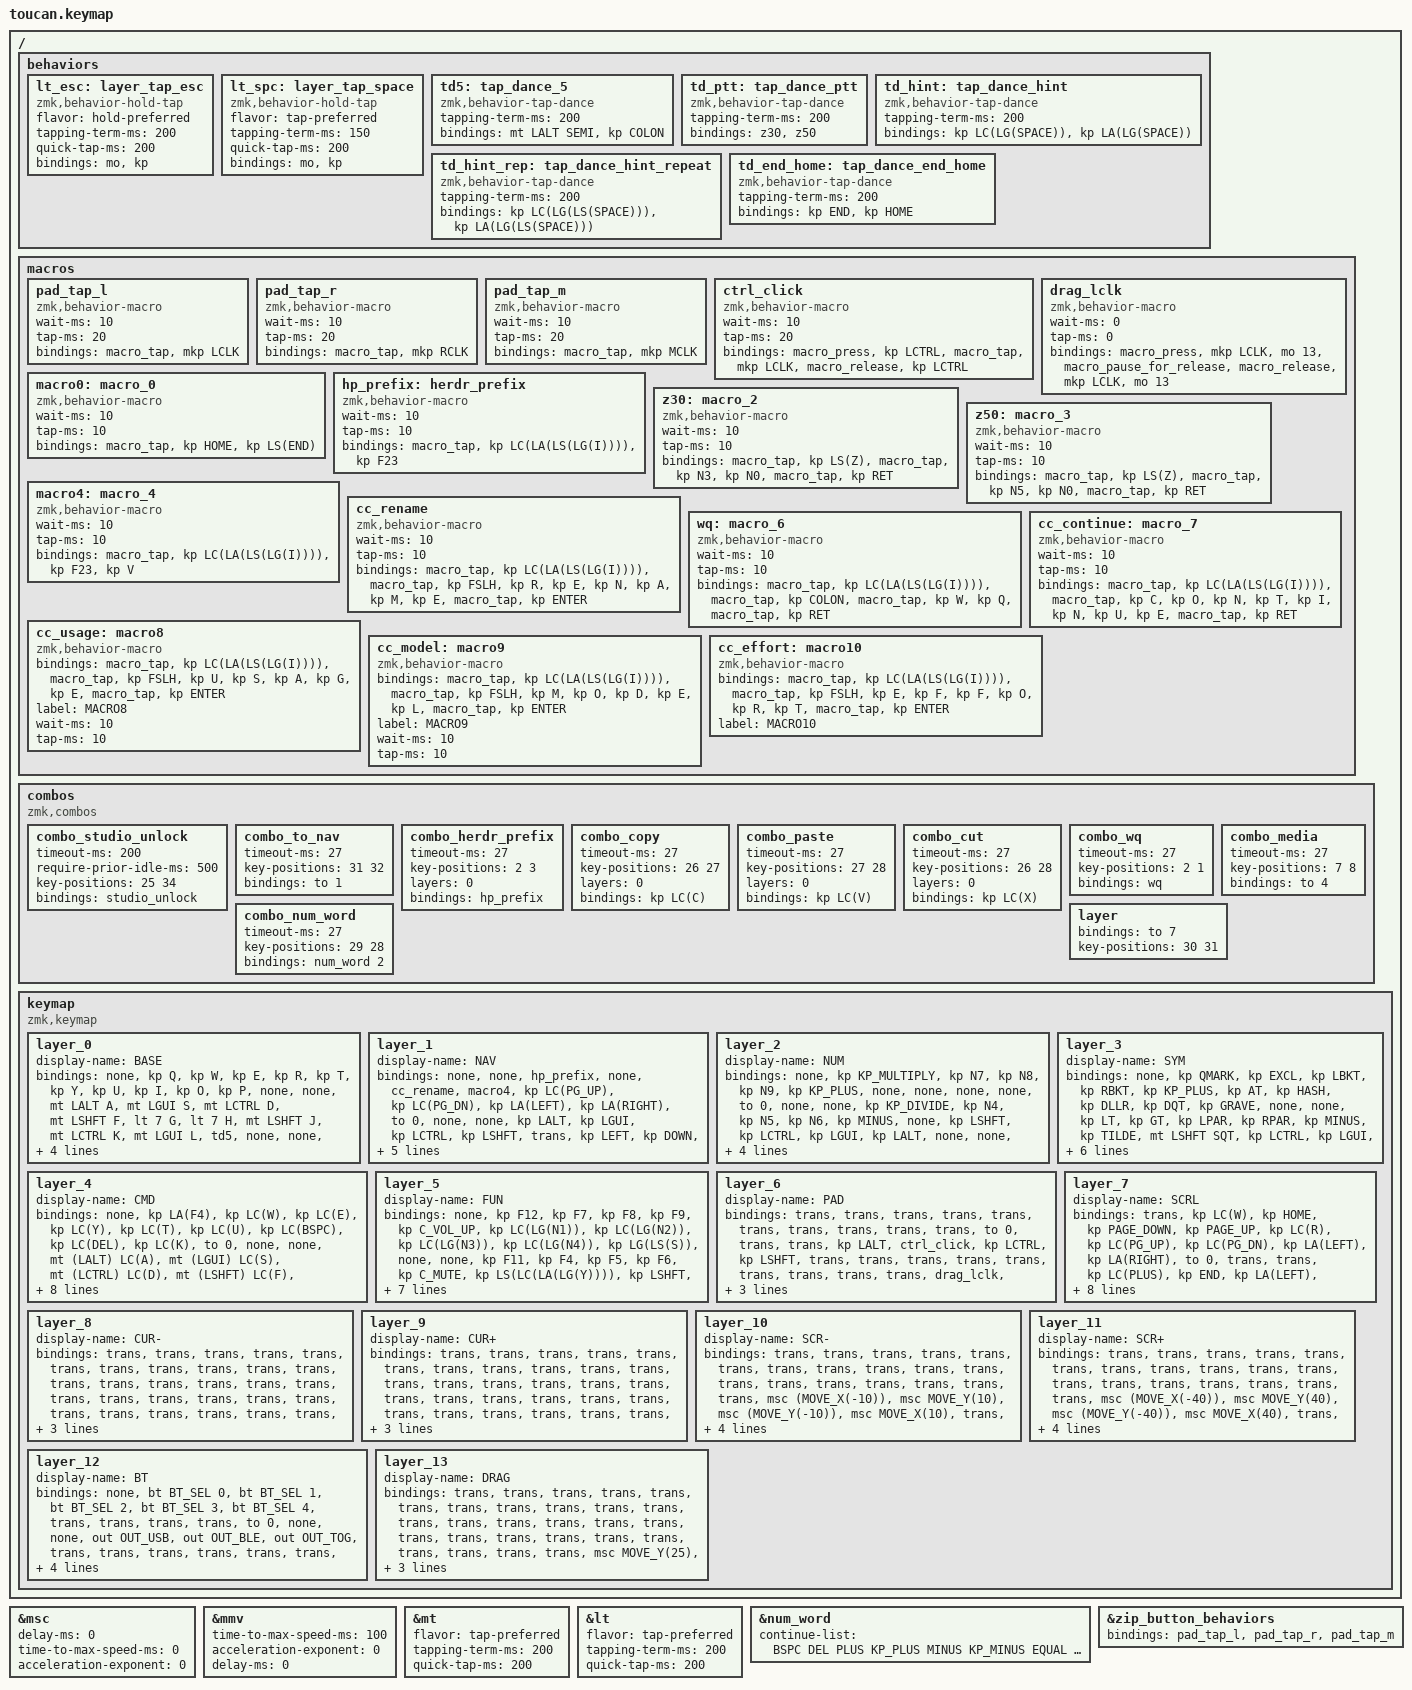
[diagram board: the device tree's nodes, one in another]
/*
 * beekeeb Toucan (dongle mode) keymap
 *
 * ⚠️ ── 2026-09-22：本檔與 Vial/QMK 正式分家，不再同步 ────────────────────
 *
 * 本檔原本是 keyboard-manager 從 beekeeb 36key.vil 產生的，檔頭寫著「do not
 * hand-edit if you intend to regenerate — change the layout in Vial, re-export,
 * and diff」。**該約定自 2026-09-22 起作廢。**
 *
 *   • 這份 ZMK keymap 是 Toucan 的**唯一真相來源**，直接手改即可。
 *   • **不要**再從 .vil 重新產生，那會洗掉底下所有 ZMK 專屬的東西——
 *     per-key hold-tap（lt_esc / lt_spc）、combos、input processor、
 *     tap-dance、num_word 的 continue-list，QMK 那邊沒有對應概念。
 *   • Piantor (Vial/QMK) 那把從此各走各的，兩邊**刻意允許發散**。
 *     `piantor/README.md` 那份「.vil 落後清單」不必再維護。
 *
 * ── 「同步」從此只有一個意思：同一把鍵盤的兩個作業系統 ────────────────────
 *
 *     同步軸                                             要不要同步
 *     ────────────────────────────────────────────────────────────
 *     ZMK：prospector-scanner(mac) ↔ …-windows(win)          ✅ 要
 *     QMK：piantor-macos-*.vil    ↔ piantor-windows-*.vil    ✅ 要
 *     ZMK ↔ QMK（Toucan ↔ Piantor）                          ❌ 不要
 *
 * 也就是 **跨 OS 要同步、跨韌體不同步**。以後講「同步」都是指前兩列。
 *
 * ⚠️ 所以根目錄 CLAUDE.md 那條「功能性改動（新增／移動／刪除某顆鍵、滾動
 *    方向）要兩個分支都做」**仍然完全有效** —— 它講的是第一列（ZMK 的兩個
 *    平台分支），跟本段作廢的 Vial 那條線無關。鍵碼各自用該平台的原生寫法
 *    （Ctrl ↔ ⌘）。不要把這兩條線搞混。
 *
 * CONVERSION-REPORT.md 仍可讀，但它只是當年一次性轉檔的歷史紀錄，
 * 不再是需要對齊的規格。
 */
/*
 * ── 本分支（prospector-scanner-windows）＝ Windows 版 ───────────────────
 *
 * 2026-09-07 從 prospector-scanner 分出來。原則：**操作語意一致，鍵碼各自
 * 原生**——不是傻傻地把 Cmd 換成 Ctrl，每一顆都對到 Windows 真正的做法。
 * 對照的權威來源是 piantor/README.md（Piantor Pro 就是這套 layout 的
 * Windows 版，2026-09-04 已實機驗證），本檔完全沿用那份定案：
 *
 *   分頁切換        ⇧⌘[ / ⇧⌘]      → Ctrl+PgUp / Ctrl+PgDn
 *   瀏覽歷史        ⌘[ / ⌘]        → Alt+← / Alt+→
 *   關程式          ⌘Q             → Alt+F4
 *   重做            ⇧⌘Z            → Ctrl+Y
 *   關/開分頁       ⌘W / ⌘T        → Ctrl+W / Ctrl+T
 *   剪貼/復原等     ⌘Z X C V B...  → Ctrl+同字母
 *   行首/行尾       ⌘← / ⌘→        → Home / End
 *   跳字            ⌥← / ⌥→        → Ctrl+← / Ctrl+→（選取加 Shift 同理）
 *   四顆刪除鍵(YUIO) ⌘⌫ ⌥⌫ ⌥⌦ ⌃K   → Ctrl+U / Ctrl+⌫ / Ctrl+Del / Ctrl+K
 *   截圖            ⇧⌘5            → Win+Shift+S
 *   切輸入法        F18            → F18（兩平台同鍵碼；Windows 由 AHK 的 $F18:: 接走）
 *   縮放            ⌘+ / ⌘0        → Ctrl+= / Ctrl+0
 *   重新整理        ⌘R             → Ctrl+R
 *   同程式切視窗    ⌘`             → Alt+Esc（Windows 沒有原生同程式循環，
 *                                     Alt+Esc 是最接近的免選單循環切換）
 *   app 焦點熱鍵    Hyper+L/E/F/T  → Ctrl+Win+1~4（工作列釘選 1~4 號）
 *   NUM 層數字      KP_N0~9/KP_DOT → 數字列 N0~9 / DOT（NumLock 關閉時
 *                                     KP_7 在 Windows 會變 Home，全部避開）
 *
 * 不變的：Hyper 巨集（⌃⌥⇧⌘+字母，HID 兩邊相同，主機端 AHK 接手）、
 * Alt+P / Alt+Space / Ctrl+Space(tmux) / Ctrl+K / F19、所有打字巨集、
 * home row 裸修飾鍵（fb3fc56 起兩把鍵盤就是「位置一致」：S=GUI、D=Ctrl）。
 *
 * ⚠️ 切輸入法 2026-10-02 起不再送 `LG(SPACE)`：鍵盤送真的 Win 時，只要放開
 *    Win 的瞬間落進 AHK 注入 Ctrl+Space 的那 1–2ms，Win 就會漏給 shell、
 *    **開始功能表跳出來**（KeyHistory 實拍：實體 LWin up 夾在注入的 Ctrl
 *    down/up 中間）。改送 F18 之後 Win 根本不出現，競態沒有地方發生。
 *    筆電內建鍵盤的 Win+Space 仍由 AHK 的 `$#Space::` 接。
 *
 * ⚠️ 下方歷史註解裡提到的 mac 鍵碼（LG(W) 之類）維持原文不改，讀的時候
 *    對照本表換算即可。
 */
/*
 * ── 層名：全部 ≤ 4 字元，這是硬約束 ─────────────────────────────────────
 *
 * 2026-09-03 改名。三個獨立的理由指向同一個上限：
 *
 *   1. Prospector 廣播欄位 `layer_name[4]` 就是 4 bytes（見
 *      status_advertisement.h）。超過直接截斷，而截斷會「撞名」——舊的
 *      CUR SLOWEST / CUR SLOW / CUR FAST 三層全部塌成 "CUR "，
 *      三個 SCRL 檔全部塌成 "SCRL"，NAV SCRL 撞 NAV。
 *   2. dongle 的儀表板版面把層名排成固定 50px 單行、不 wrap 不縮字。
 *      只要每個名字都 ≤4 字，溢出就不是「大概不會」而是不可能。
 *   3. 鍵盤自己的 nice_view 用 quinquefive_24（每字約 29px）、畫布寬
 *      144px ⇒ 一行也就 4–5 字。
 *
 *   #  名稱   說明
 *   ─────────────────────────────────────────────────────────────────
 *   0  BASE   打字
 *   1  NAV    方向鍵 / 視窗 / Claude Code 巨集
 *   2  NUM    數字鍵盤
 *   3  SYM    符號（小抄靠這名字查表，見下方 layer_3）
 *   4  CMD    Cmd 快捷 / 視窗 / 剪貼
 *   5  FUN    F1-F12 / 音量 / Hyper 巨集
 *   6  PAD    觸控板自動升起的點擊層
 *   7  SCRL   按住 G/H：觸控板變滾輪
 *   8  CUR-   游標慢檔（PAD 的 N 與左拇指 38）
 *   9  CUR+   游標快檔（PAD 的 M 與左拇指 37）
 *  10  SCR-   滾動 50%（SCRL 拇指 38/39）
 *  11  SCR+   滾動 200%（SCRL 拇指 37/40）
 *  12  BT     配對 / 輸出切換 / bootloader
 *  13  DRAG   PAD 按住 X 拖曳時升起：C / V 滾輪（2026-11-05）
 *
 * ── 2026-09-09：NAV / NUM 的 index 修回 1 / 2 ─────────────────────────
 *
 * 層 index 是照 **devicetree 節點出現的順序**算的，跟節點名字 `layer_N`
 * 無關。2026-09-06 的 fb3fc56（keymap-editor bot）把 NUM 的節點搬到 NAV
 * 前面，於是檔案變成「節點叫 layer_1、display-name 是 NAV，但實際 index
 * 是 2」——名字和 index 互相矛盾，讀檔的人（和 bot）每次都要重新推一遍。
 *
 * 這一版把 NAV 的節點搬回第一個，讓 **節點名 = display-name 的層 = 真正的
 * index** 三者一致，也回到 Piantor 一直在用的編號（`LT1(KC_ESCAPE)` = NAV、
 * `LT2(KC_BSPACE)` = NUM）與 regen.sh 的 LAYER_NAMES 順序。
 * 行為完全不變：ESC 拇指仍升 NAV、BSPC 拇指仍升 NUM，只是 &lt 的數字跟著換。
 *
 * ⇒ 以後檢查很簡單：**節點順序就是 index，兩者對不上就是有人動過順序**。
 *   跟著要核對的是 &num_word 的層參數（見下方 combo_num_word）和
 *   radii_layout.c 的 LAYERS[]，那兩處 bot 不會幫你重編號。
 *
 * ── 2026-09-04 這一版砍掉四層（17 → 13）──────────────────────────────
 *
 *   CUR (舊 9) / SCR (舊 12)  三檔調速收成兩檔，中間那顆拇指空出來。
 *                             留下的慢檔直接繼承舊中檔的速度（1.25x / 50%），
 *                             因為舊的最慢檔（0.62x / 25%）實測太鈍。
 *   HJKL (舊 14) / WHEL (舊 15)  hjkl 方向鍵⇄滾輪的 flag 層。常常誤觸而且
 *                             會 latch 住，使用者要求移除；conditional_layers
 *                             節點也跟著整個刪掉。
 *
 * 連帶刪掉的還有四組 combo_lock_*（觸控板速度鎖定）——三檔變兩檔之後，
 * 僅存的兩顆調速鍵 37/38 相鄰，拇指滾動時會誤觸 `37+38` 那組而鎖住速度。
 * 以後真的需要鎖定再重做，屆時建議用空出來的 36/41 當「鎖定修飾鍵」
 * （36+37 鎖快、36+38 鎖慢），兩顆調速鍵之間怎麼滾都不會誤觸。
 *
 * ⚠️ 改名 / 改層數時要一起動的地方：
 *   - regen.sh 的 LAYER_NAMES（層 0-5）與 Patch 3 的硬編碼 MOUSE_LAYER
 *     字串——不改的話下次 regen 會把舊名寫回來。
 *   - SYM 若改名，還要同步 nice_view_gem/widgets/cheatsheet.c 和
 *     scanner-module/.../radii_layout.c 的 CHEAT_LAYER_NAME（兩者都只
 *     認 "SYM"）。所以 SYM 刻意不改。
 *   - boards/shields/toucan/toucan-trackpad.dtsi 各處理鏈的 `layers = <>`
 *     是寫死的 index，加/刪/重排層一定要同步。
 *   - dongle 儀表板的副標表（radii_layout.c 的 LAYERS[] 與 LAYER_COUNT）
 *     是用 layer index 查的，只有「加/刪/重排層」才要動，改名不用。
 *
 * ⚠️ 刷進去後 dongle 若仍顯示舊名 → 先做 ZMK Studio 的
 *    Restore Stock Settings（flash 裡的 Studio 設定會蓋掉 keymap）。
 */

#include <behaviors/num_word.dtsi>

/* 左半改當 split central 之後才需要的：主機配對與輸出切換都歸鍵盤自己管。 */

#include <behaviors.dtsi>
#include <dt-bindings/zmk/bt.h>
#include <dt-bindings/zmk/keys.h>
#include <dt-bindings/zmk/outputs.h>
#include <dt-bindings/zmk/pointing.h>

/*
 * 鍵盤滑鼠鍵的速度（&mmv 游標 / &msc 滾輪）。這裡只管「用鍵盤推游標 / 滾輪」，
 * 觸控板本身的速度在 boards/shields/toucan/toucan-trackpad.dtsi 的 PAD_* 那組。
 *
 * ⚠️ 2026-09-02 起不再用 #define / 函式巨集，速度全部寫成字面數字——
 * nickcoutsos keymap-editor 的 parser 不吃 bindings 裡的自訂前處理器巨集，
 * 看到就整份拒收（MOVE_X/MOVE_Y/LS() 這類 ZMK 官方巨集沒問題）。
 * 代價是「改速度要同步改多處」，對照表：
 *
 * 單位（ZMK behavior-input-two-axis：speed 的單位是「每秒」，trigger-period-ms
 * 預設 16 只決定更新顆粒，不影響速度）：
 *   &mmv MOVE_x(N) = N 像素 / 秒
 *   &msc MOVE_x(N) = N 格滾輪 / 秒
 *
 *   游標基準 500（ZMK 預設 600；下面 &mmv 設 accel-exponent=0 ⇒ 全程等速）
 *     出現處：SCRL(7) 的 ±500 四格
 *   滾輪基準 25（ZMK 預設 10）
 *     出現處：SCRL(7) 的 ±25 六格（2026-09-24 起左手只剩垂直 2/4 兩格，
 *             水平的 A / G 讓給了放大與 PgDn；右手 18-21 四格不變）
 *   調速兩檔：
 *     SCR-(10)：游標 ±250   滾輪 ±10   （游標 50%、滾輪 40%）
 *     SCR+(11)：游標 ±1000  滾輪 ±40   （游標 200%、滾輪 160%）
 *
 * ── 2026-09-09 游標三檔整體砍到 1/3 ──────────────────────────────────
 *
 * 舊值 750 / 1500 / 2250 實測太衝——&mmv 是全程等速（見下面 exponent=0），
 * 1500 px/s 等於一按就飛過目標。新值把基準訂在 **500**，兩側維持
 * 50% / 100% / 200% 的兩倍關係（跟滾輪同一種刻度，好記）：
 *
 *     SCR-(10)   750 → 250
 *     SCRL(7)   1500 → 500     ← 基準
 *     SCR+(11)  2250 → 1000
 *
 * 中途曾試 250/500(基準 750)/1500，750 仍偏快而作廢；1000 這一檔是刻意
 * **沒有**回到舊基準 1500 的——真要那麼快就直接用觸控板，游標鍵的用途是
 * 「最後幾像素的微調」。要更大的頂檔就把 SCR+ 的四格改成 1500。
 *
 * ⚠️ 游標三檔的調整**只動 &mmv（鍵盤游標鍵）**。觸控板刻意沒碰——它走
 *    input processor，速度在 toucan-trackpad.dtsi 的 PAD_* 那組，而那組是
 *    **平台個人化、不跨分支 sync** 的（見 CLAUDE.md）。
 *
 * 同一天順手修掉一個左右不對稱：SCR+(11) 的滾輪左手四格是 40、右手四格
 * （位置 18-21）卻是 45，右手因此快 12.5%。已統一成 40。
 * ⇒ 現在三個滾輪檔各自左右同值：SCR- 10 / SCRL 25 / SCR+ 40，
 *   要驗證很容易——同一層的 &msc 只該出現一種絕對值。
 */
/*
 * SCRL (7) 的 42 格 bindings。
 *
 * ── 為什麼 6 和 7 不再共用同一份 ───────────────────────────────────────
 *
 * 這兩層的「進入方式」根本不同，所以能承受的內容也不同：
 *
 *   layer 6 (PAD)  觸控板一動就「自動」升起。你沒有要求它。
 *   layer 7 (SCRL) BASE 按住 G / H 才進來。是你刻意要的。
 *
 * 自動升起的層必須近乎無害——因為用完觸控板接著打字時，timeout 窗口內每一顆
 * 鍵都會落在它上面。原本兩層共用這份 bindings，等於 layer 6 有 28 格是活的、
 * 整排 home row 都是 &msc / &mmv，而位置 1 是 &kp LG(W)（關分頁）、位置 25 是
 * &kp LS(LG(T))（重開分頁）。打 the 的 e 是游標上移，打 and 三個字母全中。
 * 那不是 timeout 設太長，是這一層裝了不該裝的東西。
 *
 * 所以 layer 6 瘦身成「只有點擊 + 調速 + 逃生口」，其餘全 &trans（見下面的
 * layer_6）。進階操作全部留在這一層，反正你是刻意按住 G / H 進來的。
 *
 * 被移出 layer 6 的東西在別層都有，不會消失：
 *   位置 6-9   分頁切換 / 上下頁  → NAV 層同位置就有
 *   位置 30-33 End/PgDn/PgUp/Home → NAV 層同位置就有
 *   位置 1     &kp LG(W)          → CMD 層位置 2
 *   位置 25    &kp LS(LG(T))      → CMD 層位置 22
 *   鍵盤滾動   → 這一層
 *
 * ── 為什麼 6 / 7 必須是兩個 index ─────────────────────────────────────
 *
 * 不能合併：input-listener 只認 layer，合併之後觸控板自動升層時就會變成滾動、
 * 游標永遠動不了。也不能讓 7 去 hold 6——ZMK 的 layer state 是沒有 reference
 * counting 的共用 bitmask，temp-layer 的 timeout 會跟手動 hold 互相打架。
 *
 * 位置 10 (P) 是 &to 0：&to 會把目標層以上的所有層一併關掉，是「回到 BASE」
 * 的逃生口。（2026-09-04 之後整份 keymap **已經沒有任何 &tog**——速度鎖定
 * 那四組 combo 和 NAV 的 &tog 14 都刪了——所以沒有層會被 latch 住。唯一還會
 * 「暫時黏住」的是 CMD 位置 37 的 &sl 5，但 sticky layer 打完下一顆就自己
 * 放掉，不需要逃生口。這顆 &to 0 現在純粹是保險。）
 *
 * 拇指 36-41 不需要登記在任何名單裡：toucan-trackpad.dtsi 的
 * excluded-positions 已經留空，語意是「沒有任何鍵能提前結束滑鼠層」，所以動
 * 這裡的 bindings 不用回頭同步那邊。原因見該檔的註解。
 *
 * （這一層跟 SCR± 兩檔的 bindings 以前是用巨集展開共用的，為了
 * keymap-editor 已攤平成字面 bindings——見檔頭速度對照表。）
 */
/*
 * Hold-tap feel, carried over from the .vil's QMK settings.
 *   tapping-term-ms — Vial "Tapping Term"
 *   flavor          — derived from Vial's permissive-hold / mod-tap-interrupt
 *                     flags. If home-row mods misfire, this is the knob:
 *                     "tap-preferred" is the most forgiving, "hold-preferred"
 *                     the most eager. See zmk.dev/docs/keymaps/behaviors/hold-tap
 */
/*
 * ── 鍵盤滾輪的加速度曲線（2026-09-04 才真正啟用）─────────────────────────
 *
 * ⚠️ 先講一個之前踩到的坑：`time-to-max-speed-ms` 在 `acceleration-exponent`
 *    是 0 的時候**完全沒有作用**。ZMK 的 speed() 長這樣
 *    （zmk/app/src/behaviors/behavior_input_two_axis.c）：
 *
 *      if (... || config->time_to_max_speed_ms == 0 || accel_exp == 0) {
 *          return max_speed;      // ← 直接回傳最高速，根本不看 time-to-max
 *      }
 *      return max_speed * powf(time_fraction, accel_exp);
 *
 *    而 ZMK 的 mouse_scroll.dtsi 預設就是 acceleration-exponent = <0>。
 *
 * ⚠️ `&msc` 是**單一節點**，這條曲線 SCRL / SCR- / SCR+ 三檔共用，沒辦法
 *    只給某一檔不同的爬升時間——只有 max（各層寫死的字面數字）能分別調。
 *    這也是慢檔不敢設太低的原因：max 越小，第一格出來得越晚（max=12 要
 *    274ms），會有「按了沒反應」的錯覺。
 *
 * ⚠️ 加速度「放開就歸零」。連續看長文（按住不放）是純賺；半頁半頁地按放
 *    按放則每次都要重跑一次爬升。真的要整頁跳轉，這一層右手底排已經有
 *    M = PgDn、逗號 = PgUp，比硬捲快得多。
 *
 * 想調的話只有兩個旋鈕：這裡的 450（越大越慢熱、加速感越明顯），以及各層
 * 的 max 字面數字（見檔頭對照表）。觸控板不吃這條曲線——它走 input
 * processor，跟 &msc 無關。
 */

&msc {
    // 延遲啟動時間，0 = 隨按隨動

    delay-ms = <0>;

    // 花多少毫秒線性加速到最高速。必須搭配下面的 exponent >= 1 才有意義

    time-to-max-speed-ms = <0>;

    // 1 = 線性加速（速度從 0 開始爬）。設 0 就退回「按下去立刻全速」

    acceleration-exponent = <0>;
};

&mmv {
    // ⚠️ 下面 exponent = 0 ⇒ 這一行不會生效（理由見上面 &msc 的說明）。
    //    留著只是為了改回 exponent >= 1 時不用重查數字。

    time-to-max-speed-ms = <100>;

    // 0 = 一按下去就直接用最高速移動。游標刻意維持等速：加速度用在滾輪上
    // 是「看長文越滾越快」，用在游標上則是每次要點東西都要等它熱身。

    acceleration-exponent = <0>;

    // 延遲啟動時間 (與滾輪相同，設為 0 代表隨按隨動)

    delay-ms = <0>;
};

&mt {
    flavor = "tap-preferred";
    tapping-term-ms = <200>;
    quick-tap-ms = <200>;
};

&lt {
    flavor = "tap-preferred";
    tapping-term-ms = <200>;

    // 點一下、200ms 內再按住同一鍵 ➜ 連發該鍵的 tap 鍵碼（Enter/BSPC/Space...）
    // 而不是進層。想連發就「點、按住」，想進層就直接長按。

    quick-tap-ms = <200>;
};

&num_word {
    // 包含：退格、刪除、加號、減號、等號、小數點、乘號、除號、字母 x (以及對應的 Numpad 代碼)

    continue-list = <BSPC DEL PLUS KP_PLUS MINUS KP_MINUS EQUAL KP_EQUAL DOT KP_DOT STAR KP_MULTIPLY FSLH KP_DIVIDE X>;
};

/*
 * Trackpad: tap still clicks, tap-and-hold no longer drags.
 *
 * The central intercepts the pad's button events before they reach HID:
 * `zip_button_behaviors` is a stock ZMK input processor that swallows
 * INPUT_BTN_0/1/2 and invokes a behavior instead. Point it at macros, and a
 * macro with no `&macro_pause_for_release` does nothing on release — so a held
 * button becomes a single click and the drag can never start.
 *
 * Consequence, stated plainly: dragging with the pad alone is now impossible.
 * To drag, hold LCLK on layer PAD (left hand, D) and move the pad.
 *
 * This node must appear in EVERY processor chain on the listener — a chain
 * that matches a layer replaces the base chain rather than adding to it, so a
 * chain that omits this re-opens dragging on exactly those layers. See
 * boards/shields/toucan/toucan-trackpad.dtsi.
 *
 * ── 2026-09-03，換成 Azoteq TPS43 之後 ──────────────────────────────────
 *
 * 原本這段的理由是「Cirque Pinnacle 只有 no-taps (DIS_TAP) 一個旋鈕，而它
 * 會把 tap-to-click 和 tap-and-hold 一起關掉，所以是錯的工具」。TPS43 沒有
 * 這個限制——它的手勢是分開的 devicetree flag，`single-tap` 和
 * `press-and-hold`（＝拖曳）可以獨立開關，而 toucan_right.overlay 現在
 * 刻意只開 single-tap / two-finger-tap，沒開 press-and-hold。
 *
 * 那為什麼還留著這個 processor？兩個理由：
 *   1. 它是 pad 點擊實際的路由：BTN_0/1/2 -> &pad_tap_l / _r / _m。
 *      拿掉的話 pad 點擊會直接送原始 HID button，繞過這三個 macro。
 *   2. 感測器層級關掉拖曳是「設定」，這裡是「保險」——兩層都擋著，
 *      日後有人手癢打開 press-and-hold 也不會突然多出拖曳行為。
 */

&zip_button_behaviors { bindings = <&pad_tap_l &pad_tap_r &pad_tap_m>; };

/ {
    behaviors {
        /*
         * ── 拇指鍵的 per-key hold-tap（2026-09-22）──────────────────────────
         *
         * 全域 `&lt`（上面那個覆寫）維持 tap-preferred / 200ms **不要動** ——
         * 那是打字安全的設定。ZMK 的 `&lt` 是單一 behavior 實例，改它等於六顆
         * 拇指一起改，而 SPACE / BSPC / RET 三顆絕對不能用 hold-preferred：
         * 打字時相鄰按鍵本來就會重疊 30–80ms，hold-preferred 只要在放開拇指前
         * 有任何鍵按下就立刻判 hold，於是「空格＋下一個字母」會變成 CMD 層動作
         * —— CMD 左手那排是 LC(Z)/LC(X)/LC(C)/LC(V)/LC(W)/LA(F4)，等於打字時
         * 隨機送出 Ctrl+C（終端機裡就是 SIGINT）。BSPC 同理：退格後立刻接著打字
         * 會進 NUM 層拿到數字，而且退格沒發生。
         *
         * 所以只有下面兩顆單獨複製一份來調：
         *
         *   lt_esc  ESC 拇指 → NAV。flavor 改 hold-preferred：按了別的鍵就立刻
         *           判 hold，不必等滿 200ms。ESC 吃得下這個 flavor 的理由是它
         *           幾乎不出現在文字 roll 的中間（前後天然有停頓），不像空格。
         *
         *   lt_spc  SPACE 拇指 → CMD。flavor **維持 tap-preferred**（理由同上），
         *           只把 tapping-term 從 200 降到 150，讓進 CMD 少等 50ms。
         *           ⚠️ 代價：按空格停留超過 150ms 會被判成 hold，**那個空格就
         *           不見了**。一般按鍵停留 70–120ms，所以偶爾會中。覺得太常掉
         *           空格就把 150 調回 200，不要改 flavor。
         *
         * quick-tap-ms 兩顆都維持 200：那是「點一下、200ms 內再按住同一鍵就連發
         * tap 鍵碼」的連發路徑（按住退格連刪、按住空格連打），跟 flavor 無關，
         * 不要一起動。
         */

        lt_esc: layer_tap_esc {
            compatible = "zmk,behavior-hold-tap";
            #binding-cells = <2>;
            flavor = "hold-preferred";
            tapping-term-ms = <200>;
            quick-tap-ms = <200>;
            bindings = <&mo>, <&kp>;
        };

        lt_spc: layer_tap_space {
            compatible = "zmk,behavior-hold-tap";
            #binding-cells = <2>;
            flavor = "tap-preferred";
            tapping-term-ms = <150>;
            quick-tap-ms = <200>;
            bindings = <&mo>, <&kp>;
        };

        td5: tap_dance_5 {
            compatible = "zmk,behavior-tap-dance";
            #binding-cells = <0>;
            tapping-term-ms = <200>;
            bindings = <&mt LALT SEMI>, <&kp COLON>;
        };

        /*
         * PTT 搜推文，NAV 位置 22（原本 z30 / z50 各佔一顆）。
         * 點一下 = z30，連點兩下 = z50。單點要等 200 ms 的 tapping-term
         * 過完才送出——PTT 熱鍵不在乎這半拍。要加第三檔（例如 z100 搜
         * 爆文）就照 z30 再寫一個 macro，bindings 後面補上 <&z100>，
         * 三連點觸發。
         */

        td_ptt: tap_dance_ptt {
            compatible = "zmk,behavior-tap-dance";
            #binding-cells = <0>;
            tapping-term-ms = <200>;
            bindings = <&z30>, <&z50>;
        };

        /*
         * ── Hint 熱鍵：點一下 = AX、連點兩下 = Vision（2026-09-10）─────────
         *
         * 掛在 CMD(4) 右拇指兩顆（位置 39 / 40）。四組主機端熱鍵是：
         *
         *              單擊（AX / accessibility tree）  雙擊（Vision / CV 備援）
         *   中鍵 40    Ctrl+Win+Space                   Alt+Win+Space
         *   內側 39    Ctrl+Win+Shift+Space             Alt+Win+Shift+Space
         *              └ 無 Shift = 點一次就收          └ Shift = 連續點擊
         *
         * 也就是「Ctrl 管 AX、Alt 管 Vision、Shift 管連不連續」。Vision 只是 AX
         * 標不到東西時的備援，所以放在比較費事的雙擊上。
         *
         * ⚠️ 為什麼「切 Vision」做在韌體而不是主機端：主機端要做「快速連按兩次」
         *    得引入 timing window，第一次按就得等 200ms 才知道是不是雙擊，主線
         *    （AX）會整個變鈍。做在 tap dance 一樣是 200ms，但**只有這兩顆鍵**付
         *    這個代價，而且 Windows 那邊根本做不到 —— Ctrl+Win+Space 是 NeverClick
         *    用 RegisterHotKey 佔的，AHK 連「使用者按了第二下」都看不到。
         *
         * ⚠️ 送出去要有人接（keymap 只負責送封包）：
         *      macOS   Neru（~/.config/neru/config.toml 的 [hotkeys] 四條）
         *      Windows Ctrl+Win+Space / Alt+Win+Space = NeverClick 的兩條全域熱鍵；
         *              Ctrl+Win+Shift+Space = mousemaster 的 ui-hint 連續點擊。
         *              **Alt+Win+Shift+Space（Vision 連續）在 Windows 沒人接** ——
         *              NeverClick 沒有 repeat、mousemaster 沒有 CV，按了不會有反應。
         *              這是工具能力限制，不是 keymap 漏了。
         *
         * ⚠️ 這四組都**不是** OS 內建快捷鍵，但都撞到別人，主機端已各自處理：
         *      macOS   Ctrl+Cmd+Space = 字元檢視器、Alt+Cmd+Space = Spotlight
         *              「在 Finder 中顯示搜尋視窗」→ 使用者確認不需要，直接覆寫
         *      Windows Alt+Win+Space 原本被 PowerToys 命令選擇區佔走
         *              （RegisterHotKey）→ 已清掉它的熱鍵
         *
         * 兩個平台分支送的是**同一組 HID 鍵碼**（Win 鍵 = ⌘ 是同一顆 modifier），
         * 所以這兩個 behavior 不進「平台個人化」名單，**要兩個分支一起改**。
         */

        td_hint: tap_dance_hint {
            compatible = "zmk,behavior-tap-dance";
            #binding-cells = <0>;
            tapping-term-ms = <200>;
            bindings = <&kp LC(LG(SPACE))>, <&kp LA(LG(SPACE))>;
        };

        td_hint_rep: tap_dance_hint_repeat {
            compatible = "zmk,behavior-tap-dance";
            #binding-cells = <0>;
            tapping-term-ms = <200>;
            bindings = <&kp LC(LG(LS(SPACE)))>, <&kp LA(LG(LS(SPACE)))>;
        };

        /*
         * SCRL(7) 位置 29（B）＝ Piantor 的 TD(9)。點一下 End、連點兩下 Home。
         *
         * 2026-09-24 才搬進來。這顆原本是 &kp ESC，改版時 Esc 讓給位置 1（Q，
         * 對齊 Piantor），空出來的格子接手左手的「行首 / 行尾」。右手底排本來
         * 就有 N = End、句點 = Home，這顆是給「按住 H、只剩左手」時用的。
         *
         * End 放單擊、Home 放雙擊，因為 End 用得頻繁得多。代價同 td_ptt /
         * td_hint：單點要等 200ms 的 tapping-term 過完才送得出去。
         *
         * HID 鍵碼兩個平台相同（macOS 的 End / Home 就是 fn+→ / fn+←），
         * 所以**不進平台個人化名單，兩個分支一起改**。
         */

        td_end_home: tap_dance_end_home {
            compatible = "zmk,behavior-tap-dance";
            #binding-cells = <0>;
            tapping-term-ms = <200>;
            bindings = <&kp END>, <&kp HOME>;
        };
    };

    /*
     * 2026-09-04：這裡原本有一個 conditional_layers 節點（NAV(1) + HJKL(14)
     * ⇒ WHEL(15)，把 NAV 的 hjkl 四格換成滾輪）。整套 HJKL / WHEL 機制已經
     * 連同那兩層一起刪掉——&tog 14 太容易誤觸，而且會 latch 住，回 BASE 之後
     * 得再按一次才解得開。鍵盤滾動請用 SCRL(7)（按住 G / H）。
     */

    macros {
        /*
         * The three pad-click macros. `&macro_tap` presses and releases within
         * tap-ms; nothing is queued for the release, which is the whole point —
         * see the &zip_button_behaviors note at the top of this file.
         */

        pad_tap_l: pad_tap_l {
            compatible = "zmk,behavior-macro";
            #binding-cells = <0>;
            wait-ms = <10>;
            tap-ms = <20>;
            bindings = <&macro_tap>, <&mkp LCLK>;
        };

        pad_tap_r: pad_tap_r {
            compatible = "zmk,behavior-macro";
            #binding-cells = <0>;
            wait-ms = <10>;
            tap-ms = <20>;
            bindings = <&macro_tap>, <&mkp RCLK>;
        };

        pad_tap_m: pad_tap_m {
            compatible = "zmk,behavior-macro";
            #binding-cells = <0>;
            wait-ms = <10>;
            tap-ms = <20>;
            bindings = <&macro_tap>, <&mkp MCLK>;
        };

        /*
         * Ctrl+左鍵點擊（終端機開連結／檔案路徑、瀏覽器新分頁開連結…）。
         * 放在 PAD / SCRL 的左拇指最外側（位置 36）。一按就是一次完整點擊，
         * 不能按住拖曳；要拖曳就按住 LCLK（X）。
         */

        ctrl_click: ctrl_click {
            compatible = "zmk,behavior-macro";
            #binding-cells = <0>;
            wait-ms = <10>;
            tap-ms = <20>;
            bindings =
                <&macro_press>,
                <&kp LCTRL>,
                <&macro_tap>,
                <&mkp LCLK>,
                <&macro_release>,
                <&kp LCTRL>;
        };

        /*
         * 按住的左鍵＋升起 DRAG(13)（2026-11-05，PAD 的 X / 位置 26）。
         * 按住拖曳選取時，C / V 變成 SCRL 的 J / K（滾輪下 / 上），
         * 不用放開左鍵就能捲動。放開就同時放掉左鍵與 DRAG。
         */

        drag_lclk: drag_lclk {
            compatible = "zmk,behavior-macro";
            #binding-cells = <0>;
            wait-ms = <0>;
            tap-ms = <0>;
            bindings =
                <&macro_press &mkp LCLK &mo 13>,
                <&macro_pause_for_release>,
                <&macro_release &mkp LCLK &mo 13>;
        };

        macro0: macro_0 {
            compatible = "zmk,behavior-macro";
            #binding-cells = <0>;
            wait-ms = <10>;
            tap-ms = <10>;
            bindings = <&macro_tap>, <&kp HOME &kp LS(END)>;
        };

        /*
         * ── Hyper+I：強制把主機的嘸蝦米切成英文（2026-09-22）─────────────────
         *
         * 送一顆 Hyper+I（Ctrl+Alt+Shift+Win+I）。主機端由 AutoHotkey 的
         * `^!+#i::ImeForceEnglish()` 接走，用 IMM32 的 IMC_SETOPENSTATUS 寫 0。
         * ⚠️ 這顆鍵**不會漏進前景 app**（AHK 沒加 `~`，會吃掉）。
         *
         * 為什麼需要：中文模式下，鍵盤 macro 打出來的 ASCII 會被輸入法整串吃掉
         * （/rename 變成組字），herdr 的 prefix 之後要按的字母也一樣到不了 herdr。
         *
         * 為什麼是 I：Ctrl+Alt+Shift+Win 就是微軟「Office 鍵」的模擬 chord，系統
         * 用 RegisterHotKey 搶註了 D L N O P T W X Y 九個字母（用一般註冊會完全
         * 沒反應且無錯誤訊息）。I 不在那九顆裡。全機登記表：
         * MyConfig/docs/spec/hyperkeys.spec.md。
         *
         * ⚠️ 用法一律是「**放在 macro 的第一個動作**」，靠順序保證，不插延遲。
         *    曾評估在後面插 `&macro_wait_time 80`，使用者認為太久而否決 ——
         *    AHK 的 SendMessage 實測遠快於 macro 的 10ms wait-ms，但不是硬保證；
         *    真的遇到偶發失敗，旋鈕就是在該 macro 裡插 `<&macro_wait_time N>`。
         *
         * ⚠️ macOS 刻意不做（2026-09-22 使用者決定）。mac 的中/英是「選哪個輸入
         *    來源」而不是 IME 的 open status，Hammerspoon 那邊要另寫一套；
         *    Piantor 的 macOS .vil（分支 prospector-scanner）也沒有跟著改。
         *
         * ⚠️ 這顆刻意**內嵌重複**在每個需要的 macro 裡，沒有抽成一個 `&ime_en`
         *    macro 再互相呼叫。ZMK 的巢狀 macro（macro 裡呼叫 macro）文件上說
         *    可行、但本 repo 沒實證過，而驗證成本是「build → 刷韌體 → 手測」。
         *    重複一個 token 換掉這份不確定性，划算。要改成巢狀之前先實測。
         */
        /*
         * herdr 的 prefix：先切英文（Hyper+I），再送 F23。
         * combo（W+E）與 NAV 層的 W（位置 2）都綁這顆，兩條路徑行為一致。
         */

        hp_prefix: herdr_prefix {
            compatible = "zmk,behavior-macro";
            #binding-cells = <0>;
            wait-ms = <10>;
            tap-ms = <10>;
            bindings = <&macro_tap>, <&kp LC(LA(LS(LG(I)))) &kp F23>;
        };

        /*
         * 2026-09-11：macro_1（claude，打字 claude+Enter）連定義刪除，
         * 使用者不用了。同批刪掉的還有 cc_clear / cc_exit（見下）。
         */

        z30: macro_2 {
            compatible = "zmk,behavior-macro";
            #binding-cells = <0>;
            wait-ms = <10>;
            tap-ms = <10>;
            bindings =
                <&macro_tap>,
                <&kp LS(Z)>,
                <&macro_tap>,
                <&kp N3 &kp N0>,
                <&macro_tap>,
                <&kp RET>;
        };

        z50: macro_3 {
            compatible = "zmk,behavior-macro";
            #binding-cells = <0>;
            wait-ms = <10>;
            tap-ms = <10>;
            bindings =
                <&macro_tap>,
                <&kp LS(Z)>,
                <&macro_tap>,
                <&kp N5 &kp N0>,
                <&macro_tap>,
                <&kp RET>;
        };

        /*
         * macro4 = herdr 的 prefix + v ＝ copy_mode。掛在 NAV 層位置 5。
         *
         * ⚠️ 2026-09-22：原本送的是 `&kp LC(SPACE) &kp V`，那是**舊的 mac
         *    prefix**（ctrl+space）—— 在這台 Windows 上從 2026-09-11 起就一直是
         *    壞的（Windows 那時的 prefix 是 ctrl+alt+space，而且 Ctrl+Space 在
         *    Windows 直接被系統 IME 中英熱鍵吃掉，根本到不了終端機）。
         *    prefix 這次統一成 F23，順手把這顆一起遷移，兩平台都會動了。
         */

        macro4: macro_4 {
            compatible = "zmk,behavior-macro";
            #binding-cells = <0>;
            wait-ms = <10>;
            tap-ms = <10>;
            bindings = <&macro_tap>, <&kp LC(LA(LS(LG(I)))) &kp F23 &kp V>;
        };

        /*
         * Claude Code 的斜線指令。跟 cc_usage / cc_model 一樣，打完直接送出。
         * 不想要自動送出的話，把最後那組 <&macro_tap>, <&kp ENTER> 兩行
         * 刪掉即可（只打字、不按 Enter）。
         *
         * 2026-09-11 拔掉 cc_clear（/clear）與 cc_exit（/exit），連同 claude
         * （見上面 macro_1 的位置）——使用者不用了，定義一併刪除。
         */

        cc_rename: cc_rename {
            compatible = "zmk,behavior-macro";
            #binding-cells = <0>;
            wait-ms = <10>;
            tap-ms = <10>;
            bindings =
                <&macro_tap>,
                <&kp LC(LA(LS(LG(I))))>,
                <&macro_tap>,
                <&kp FSLH &kp R &kp E &kp N &kp A &kp M &kp E>,
                <&macro_tap>,
                <&kp ENTER>;
        };

        wq: macro_6 {
            compatible = "zmk,behavior-macro";
            #binding-cells = <0>;
            wait-ms = <10>;
            tap-ms = <10>;
            bindings =
                <&macro_tap>,
                <&kp LC(LA(LS(LG(I))))>,
                <&macro_tap>,
                <&kp COLON>,
                <&macro_tap>,
                <&kp W &kp Q>,
                <&macro_tap>,
                <&kp RET>;
        };

        cc_continue: macro_7 {
            compatible = "zmk,behavior-macro";
            #binding-cells = <0>;
            wait-ms = <10>;
            tap-ms = <10>;
            bindings =
                <&macro_tap>,
                <&kp LC(LA(LS(LG(I))))>,
                <&macro_tap>,
                <&kp C &kp O &kp N &kp T &kp I &kp N &kp U &kp E>,
                <&macro_tap>,
                <&kp RET>;
        };

        cc_usage: macro8 {
            compatible = "zmk,behavior-macro";
            #binding-cells = <0>;
            bindings =
                <&macro_tap>,
                <&kp LC(LA(LS(LG(I))))>,
                <&macro_tap>,
                <&kp FSLH &kp U &kp S &kp A &kp G &kp E>,
                <&macro_tap>,
                <&kp ENTER>;

            label = "MACRO8";
            wait-ms = <10>;
            tap-ms = <10>;
        };

        cc_model: macro9 {
            compatible = "zmk,behavior-macro";
            #binding-cells = <0>;
            bindings =
                <&macro_tap>,
                <&kp LC(LA(LS(LG(I))))>,
                <&macro_tap>,
                <&kp FSLH &kp M &kp O &kp D &kp E &kp L>,
                <&macro_tap>,
                <&kp ENTER>;

            label = "MACRO9";
            wait-ms = <10>;
            tap-ms = <10>;
        };

        cc_effort: macro10 {
            compatible = "zmk,behavior-macro";
            #binding-cells = <0>;
            bindings =
                <&macro_tap>,
                <&kp LC(LA(LS(LG(I))))>,
                <&macro_tap>,
                <&kp FSLH &kp E &kp F &kp F &kp O &kp R &kp T>,
                <&macro_tap>,
                <&kp ENTER>;

            label = "MACRO10";
        };
    };

    combos {
        compatible = "zmk,combos";

        combo_studio_unlock {
            // Hand-added, not from the .vil — see regen.sh.
            // Z + / together, after a brief pause. Unlocks ZMK Studio.

            timeout-ms = <200>;
            require-prior-idle-ms = <500>;
            key-positions = <25 34>;
            bindings = <&studio_unlock>;
        };

        combo_to_nav {
            timeout-ms = <27>;
            key-positions = <31 32>;
            bindings = <&to 1>;

            // KC_M + KC_COMMA → TO(1)：目標一直是 NAV，index 2026-09-09 修回 1
        };

        /*
         * ── 2026-09-22：combo_tmux 刪除，位置讓給貼上 ───────────────────────
         *
         * 原本 <27 28>（C+V）送 &kp LC(SPACE)，那是 tmux prefix 的遺留。兩個
         * 理由讓它必須走：
         *   1. tmux 已於 2026-09-11 退場，herdr 的 prefix 是 Ctrl+Alt+Space。
         *   2. **Windows 上 Ctrl+Space 是系統 IME 的中英切換熱鍵**（登記在
         *      HKCU\Control Panel\Input Method\Hot Keys\00000070），所以這組
         *      combo 在這台的實際效果是「切換中英輸入」，不是任何有用的東西。
         */
        /*
         * ── herdr prefix 改用 combo（2026-09-22）────────────────────────────
         *
         * 原本掛在 NAV 層的 W（位置 2；那顆同日下午一起改成 &kp F23，見下面
         * 那段補充），要按
         * 到它得先按住左拇指 ESC 進 NAV。問題是 &lt 是 tap-preferred/200ms：
         * 拇指按不滿 200ms 就滾去按 W，拇指會被判成 **tap = ESC**，herdr 收到
         * 的是一個裸 ESC（client log 的 `flushing lone escape ... bytes=[27]`
         * 就是這個），prefix 整個沒送出去。
         *
         * combo 的 27ms 窗口沒有這個問題，也不必先進層。prefix 這種高頻又要求
         * 即時的鍵本來就不該放在 layer-hold 後面。
         */
        /*
         * ⚠️ 2026-09-22 下午追加：prefix 從 Ctrl+Alt+Space 改成 **F23**。
         *
         * 上面那段（今天早上寫的）以為裸 ESC 只來自 &lt 的 tap-preferred 誤判，
         * 所以改用 combo 就沒事了。**不對，那只解決了一半。** combo 韌體 10:23
         * build 完刷進去之後，13:40 的 client log 還是連噴七筆同樣的
         * `flushing lone escape ... bytes=[27]`：
         *
         *   firmware 送出的是乾淨的 Ctrl+Alt+Space、完全沒有 ESC，
         *   herdr 卻還是收到裸 ESC ⇒ 那個 ESC 是**主機端**加的，不是鍵盤產的。
         *
         * 成因：終端機編碼 Alt 組合鍵的方式就是 `ESC` + <鍵>。Ctrl+Alt+Space 到
         * Windows Terminal 會變成 ESC + NUL 兩個 byte，而第二個 byte（NUL ＝
         * Ctrl+Space）正好撞上系統註冊的 IME 中英熱鍵（Input Method\Hot Keys
         * \00000070）、嘸蝦米又拿 Space 當送出字根鍵 —— 被吃掉。herdr 等不到第
         * 二個 byte 就逾時，把裸 ESC 沖進 pane。
         *
         * ⇒ 只要 prefix 帶 Alt，這條 ESC 拆解路徑就一定存在，鍵盤端再乾淨也沒用。
         *   F23 根本不是組合鍵，**沒有修飾鍵可以被拆散**：終端機送 F 鍵是一段
         *   完整的 CSI 序列、由終端機自己一次寫出，輸入法也不碰 F 鍵（不是組字
         *   鍵）。已實測穿得過 WT/ConPTY 到 herdr（見 herdr config.toml 的
         *   workspace_picker 那段），同路徑的 Ctrl+F24 也天天在用。
         *
         * ⚠️ 為什麼**不能**選 Ctrl+字母 —— 這顆 prefix 是 combo 發射的，而
         *   **combo 在任何 app 裡都會發射**。在 herdr 裡 herdr 會攔下來，但誤按
         *   在 Chrome / VS Code 上那顆鍵就真的生效。選鍵條件因此不只是「pane 裡
         *   沒人用」，還要「**誤按在別的地方無害**」。當天連踩兩次：
         *     · Ctrl+O —— 撞 Claude Code 的 app:toggleTranscript，pane 內就衝突
         *     · Ctrl+Q —— pane 內乾淨（四邊 0 命中），但**誤按會關掉程式**
         *   Ctrl+字母的候選全被這條篩掉。F23 沒有任何程式綁 → 誤按完全沒事。
         *
         * ⚠️ Hyper（Ctrl+Alt+Shift+Win）也不行：Win 鍵永遠到不了終端機程式
         *   （WT 官方：the terminal will never receive that binding）。
         *
         * ⚠️ F23 是登記在 MyConfig/docs/spec/fkeys.spec.md 的中性訊號鍵，
         *   **F13–F22 與 F24 全部有主，F23 是唯一空著的一顆**。要再動 F 鍵之前
         *   先查那張表。
         *
         * combo 本身保留 —— 它解決的是「不必先按住拇指進 NAV」，那個好處還在，
         * 而且跟這次換鍵是正交的兩件事。
         */

        combo_herdr_prefix {
            timeout-ms = <27>;
            key-positions = <2 3>;   // W + E
            layers = <0>;
            bindings = <&hp_prefix>;
        };

        /*
         * ── 剪貼簿三連（2026-09-22）────────────────────────────────────────
         *
         *   X+C = 複製  <26 27>      相鄰
         *   C+V = 貼上  <27 28>      相鄰
         *   X+V = 剪下  <26 28>      跳過中間的 C
         *
         * 全部落在 XCV 那一排、全是 plain &kp，零修飾鍵衝突。X+C 與 C+V 共用
         * 位置 27 沒問題——ZMK 比對的是完整鍵位集合，兩顆的組合各自唯一。
         *
         * ⚠️ 為什麼不用 D+F 當複製（原本的想法）：位置 15/16 是 home row mods
         *    `&mt LCTRL D` / `&mt LSHFT F`，D+F 同時按就是「用 home row 打
         *    Ctrl+Shift」的手勢。27ms 窗口一旦命中，Ctrl+Shift+T / Ctrl+Shift+P
         *    /Ctrl+Shift+←→、乃至 Windows Terminal 自己的 Ctrl+Shift+C/V 全部
         *    會變成複製，而且命中與否取決於兩指差幾 ms ＝ 間歇性故障。
         *
         * ⚠️ `layers = <0>` 只在 BASE 生效，是刻意的：NAV 層位置 26/27/28 是
         *    `&kp LA(P)` / `&cc_continue` / `&cc_usage`，沒有限制的話在 NAV 上
         *    連續按那幾個巨集會被這三組 combo 蓋掉。要改成全層生效就把
         *    `layers` 那行刪掉。
         */

        combo_copy {
            timeout-ms = <27>;
            key-positions = <26 27>;  // X + C
            layers = <0>;
            bindings = <&kp LC(C)>;
        };

        combo_paste {
            timeout-ms = <27>;
            key-positions = <27 28>;  // C + V
            layers = <0>;
            bindings = <&kp LC(V)>;
        };

        combo_cut {
            timeout-ms = <27>;
            key-positions = <26 28>;  // X + V
            layers = <0>;
            bindings = <&kp LC(X)>;
        };

        combo_wq {
            timeout-ms = <27>;
            key-positions = <2 1>;
            bindings = <&wq>;

            // KC_W + KC_Q → M6
        };

        combo_media {
            timeout-ms = <27>;
            key-positions = <7 8>;
            bindings = <&to 4>;

            // KC_U + KC_I → TO(4)
        };

        /*
         * V + B ➔ num_word：自動升起 NUM 層連打數字，打到不在 continue-list
         * 的鍵就自己掉下來（continue-list 在上面的 &num_word 覆寫）。
         *
         * ⚠️ 下面 bindings 的 `2` 是寫死的層 index，keymap-editor **不會**幫它
         *    重編號。2026-09-06 的 fb3fc56（editor bot，訊息寫 "swap ctrl cmd"）
         *    把 NUM 的節點搬到 NAV 前面——層 index 是照 devicetree 的節點順序算
         *    的，不是照 layer_N 的名字——所以 NUM 從 2 變成 1。editor 把它認得的
         *    &lt / &mo / &to 全部跟著改了，卻不知道 &num_word 的參數也是層
         *    index，於是這組 combo 變成升 NAV，症狀就是「num_word 不見了」。
         *    2026-09-09 節點順序修回 NAV, NUM，這一行也跟著回到 2。
         *    以後只要層的順序動過，這一行都要手動核對。
         *    （不能改寫成 #define：editor 的 parser 不吃 bindings 裡的自訂巨集，
         *      見檔頭。）
         */

        combo_num_word {
            timeout-ms = <27>; // 依照你其他 combo 的習慣設定為 27 毫秒
            key-positions = <29 28>; // 對應 BASE 層的 V (28) 和 B (29)
            bindings = <&num_word 2>; // 2 = NUM（節點順序：BASE, NAV, NUM…）
        };

        layer {
            bindings = <&to 7>;
            key-positions = <30 31>;
        };

        /*
         * 2026-09-04：這裡原本有四組 combo_lock_*（拇指兩顆同時按 ⇒ &tog 8 /
         * &tog 10，鎖住觸控板游標的最慢 / 最快檔）。跟著三檔收成兩檔一起刪掉。
         *
         * 刪掉的理由是位置衝突：調速鍵從「36 快 / 37 中 / 38 慢」改成
         * 「37 快 / 38 慢」之後，僅存的兩顆變成相鄰，而 combo_lock_slowest_l
         * 正好就是 <37 38>——拇指從快檔滾到慢檔時只要在 50 ms 內壓到兩顆就會
         * 鎖住，是個標準的 latch 陷阱。
         *
         * 以後要重做的話，建議用空出來的 36 / 41 當「鎖定修飾鍵」：
         *   左手 36+37 鎖快、36+38 鎖慢；右手 41+40 鎖快、41+39 鎖慢。
         * 這樣兩顆調速鍵之間怎麼滾都不會誤觸。
         *
         * 屆時 `layers` 名單一定要含被鎖的那兩層（ZMK 是拿「按下第一顆鍵當下
         * 最高的 active layer」去比對，見 combo.c 的
         * zmk_keymap_highest_layer_active），少了它們鎖上就解不開；而且刻意
         * 不要含 SCRL(7)——鎖住滾動速度是陷阱，放開 G 之後觸控板會在非滾動
         * 狀態持續滾動。
         */
    };

    keymap {
        compatible = "zmk,keymap";

        layer_0 {
            display-name = "BASE";
            bindings = <
&none  &kp Q  &kp W  &kp E  &kp R  &kp T  &kp Y  &kp U  &kp I  &kp O  &kp P  &none  &none  &mt LALT A  &mt LGUI S  &mt LCTRL D  &mt LSHFT F  &lt 7 G  &lt 7 H  &mt LSHFT J  &mt LCTRL K  &mt LGUI L  &td5  &none  &none  &kp Z  &kp X  &kp C  &kp V  &kp B  &kp N  &kp M  &kp COMMA  &kp F18  &kp FSLH  &none  &lt 3 TAB  &lt_spc 4 SPACE  &lt_esc 1 ESC  &lt 2 BSPC  &lt 5 RET  &lt 3 F19
            >;
        };

        layer_1 {
            display-name = "NAV";

            /*
             * ⚠️ 2026-09-04 更正：這裡原本寫「位置 3 和 4 是手動加的
             *    &studio_unlock / &bootloader」——**那已經不是事實**。
             *    5b6ab49 當年確實把它們放在位置 3/4，但 3860f1b（add macro）
             *    起陸續被 Claude Code 巨集覆蓋，現在是：
             *
             *      0 &none      1 &none       2 &kp F23
             *      3 &none      4 &cc_rename  5 &macro4
             *
             *    也就是 1 / 3 現在都是空位（1 原本是 &cc_exit，2026-09-11
             *    連定義一起拔掉，見下）。
             *
             *    兩條逃生路徑沒有消失，只是搬家了，不用急著補回來：
             *      Studio 解鎖 → combo_studio_unlock（Z + /，見上面 combos）
             *      bootloader → BT(12) 層的 B 和 N 兩顆（見 layer_12 註解）
             *
             *    regen.sh 的 Patch 2 仍然假設位置 0-4 是五顆 &none，所以
             *    重跑 regen 會直接硬錯——那是刻意的，見 regen.sh 檔頭。
             *
             * Position 22 is hand-changed:
             *   22 &td_ptt — z30 / z50 合併：點一下 z30、連點兩下 z50。
             *
             * herdr 的 prefix（位置 2 = W，主機端要有 herdr 在跑才有反應）：
             * 2026-09-11 先放在 29（B，蓋掉 &claude），同日搬到 2（W），29 歸
             * &none。cc_exit（1）、cc_clear（原本的 2）和 &claude 三個 Claude
             * Code 巨集同時拔掉——使用者不用了，**定義一併刪除**（不留 M12/M13
             * 式的備用），要回收去翻 git 歷史。
             *
             * ⚠️ 2026-09-22 送出的鍵從 &kp LC(LA(SPACE))（Ctrl+Alt+Space）改成
             *    &kp F23。帶 Alt 的 prefix 在終端機會被拆成 `ESC`+<鍵>，第二個
             *    byte 被輸入法吃掉就只剩裸 ESC；而 Ctrl+字母雖然沒這問題，卻會
             *    在「combo 誤按在別的 app」時真的生效。F23 兩者都躲掉 ——
             *    完整實測證據與推理見上面 combo_herdr_prefix 的註解。
             *    主機端對應改動：MyConfig 的 dot_config/herdr/config.toml.tmpl
             *    （prefix = "f23"，兩平台統一）與 dot_wezterm.lua，
             *    ＋ docs/spec/fkeys.spec.md 的 F23 登記。
             *    ⚠️ 位置 5 的 &macro4（prefix+v ＝ copy_mode）也一起改了。
             *
             * 位置 34 以前是 &tog 14（hjkl 方向鍵 ⇄ 滾輪切換）。2026-09-04
             * 連同 HJKL / WHEL 兩層一起刪掉，改成 &trans 落回 BASE 的 `/`。
             * 這顆同時是 combo_studio_unlock 的一半（<25 34>），combo 是看
             * 位置不是看 binding，所以改成 &trans 不影響解鎖。
             */

            bindings = <
&none  &none  &hp_prefix  &none  &cc_rename  &macro4  &kp LC(PG_UP)  &kp LC(PG_DN)  &kp LA(LEFT)  &kp LA(RIGHT)  &to 0  &none  &none  &kp LALT  &kp LGUI  &kp LCTRL  &kp LSHFT  &trans  &kp LEFT  &kp DOWN  &kp UP  &kp RIGHT  &kp LC(LS(T))  &none  &none  &cc_effort  &kp LA(P)  &cc_continue  &cc_usage  &none  &kp END  &kp PG_DN  &kp PG_UP  &kp HOME  &kp LC(W)  &none  &none  &none  &kp ESC  &kp BSPC  &kp DEL  &kp F19
            >;
        };

        layer_2 {
            display-name = "NUM";

            /*
             * ⚠️ 位置 34（右手小指底排，BASE 的 `/`）是 BT 層的**唯一入口**。
             *
             * 2026-09-09 從 CMD 位置 40（右拇指中鍵）搬過來的——那顆太好按，
             * 讓給 Ctrl+Win+Space。挑這裡的理由：
             *   1. 這一層右手本來整片是 &none（位置 6-9、30-34 全空），
             *      所以佔掉它不會擠掉任何現有鍵，也沒有既有肌肉記憶。
             *   2. 進 NUM 靠的是**右**拇指 BSPC，位置 34 又是右手小指最外側
             *      ⇒ 同手大跨度，打字時絕對不可能誤觸。
             *   3. 按住之後**左手整隻是自由的**，而 BT 層要按的東西剛好都在
             *      左邊：BT_SEL 0-4 在位置 1-5、OUT_USB/BLE/TOG 在 13-15、
             *      BT_CLR 在 25。所以「難按」只針對進入，配對操作不受影響。
             *
             * 完整手勢：按住右拇指 BSPC + 右小指 `/`，左手選 profile。
             * bootloader（位置 29/30）也在這條路徑上，刷機前要記得。
             */

            bindings = <
&none  &kp KP_MULTIPLY  &kp N7  &kp N8  &kp N9  &kp KP_PLUS  &none  &none  &none  &none  &to 0  &none  &none  &kp KP_DIVIDE  &kp N4  &kp N5  &kp N6  &kp MINUS  &none  &kp LSHFT  &kp LCTRL  &kp LGUI  &kp LALT  &none  &none  &kp X  &kp N1  &kp N2  &kp N3  &kp EQUAL  &none  &none  &none  &none  &mo 12  &none  &kp N0  &kp DOT  &kp PRCNT  &kp BACKSPACE  &kp ENTER  &kp F19
            >;
        };

        layer_3 {
            /*
             * SYM 是第一個被縮短的層名（當年只有它超標），現在全部 13 層
             * 都收進 4 字元了——理由見檔頭的層名表。
             *
             * ⚠️ 這一個名字比其他層多兩個綁定：小抄是用「層名字串」查表的，
             * 不是用 index。改成別的字要同步這兩處，否則小抄直接消失：
             *   boards/shields/nice_view_gem/widgets/cheatsheet.c 的 .layer_name
             *   scanner-module/.../src/radii_layout.c 的 CHEAT_LAYER_NAME
             * 所以 SYM 刻意維持原樣。
             */

            display-name = "SYM";
            bindings = <
&none  &kp QMARK  &kp EXCL  &kp LBKT  &kp RBKT  &kp KP_PLUS  &kp AT  &kp HASH  &kp DLLR  &kp DQT  &kp GRAVE  &none  &none  &kp LT  &kp GT  &kp LPAR  &kp RPAR  &kp MINUS  &kp TILDE  &mt LSHFT SQT  &kp LCTRL  &kp LGUI  &mt LALT COLON  &none  &none  &kp PIPE  &kp AMPS  &kp LBRC  &kp RBRC  &kp KP_EQUAL  &kp CARET  &kp STAR  &kp COMMA  &kp BSLH  &kp FSLH  &none  &kp UNDER  &kp DOT  &kp PRCNT  &kp LS(LC(LA(LG(E))))  &kp LA(SPACE)  &kp LC(LG(R))
            >;
        };

        layer_4 {
            display-name = "CMD";

            /*
             * ── 2026-09-09 右拇指兩顆換成主機端全域熱鍵 ──────────────────
             *
             *   位置 39（右拇指最內側）  &mo 2（升 NAV）   → Ctrl+Win+Shift+Space
             *   位置 40（右拇指中鍵）    &mo 12（升 BT）   → Ctrl+Win+Space
             *
             * ── 2026-09-10 這兩顆再升級成 tap dance ──────────────────────
             *   39 = &td_hint_rep   單擊 Ctrl+Win+Shift+Space（AX 連續點擊）
             *                       雙擊 Alt+Win+Shift+Space（Vision 連續點擊）
             *   40 = &td_hint       單擊 Ctrl+Win+Space（AX 單次點擊）
             *                       雙擊 Alt+Win+Space（Vision 單次點擊）
             * 定義與完整理由見檔案上方 behaviors 的 td_hint / td_hint_rep 註解。
             * 代價：單擊要等 200ms 的 tapping-term 過完才送出（同 td_ptt）。
             *
             * 理由是位置划算：這兩顆是右拇指最順的位置，而原本掛的兩個功能
             * 都另有入口——NAV 用左拇指 ESC 就到（而且 CMD 本身是左拇指
             * SPACE 按住的，同手再去升 NAV 本來就彆扭）；BT 一個月用不到
             * 一次，搬到 NUM 位置 34（見 layer_2 的註解）。
             *
             * ⚠️ Ctrl+Win+Space / Ctrl+Win+Shift+Space **不是 OS 內建快捷鍵**，
             *    送出去要有人接：Windows 這邊是 AHK、macOS 是 Hammerspoon /
             *    Raycast。keymap 只負責送封包，主機端沒設就等於沒反應。
             *    兩個平台分支送的是**同一組 HID 鍵碼**（Win 鍵 = ⌘ 是同一顆
             *    modifier），所以這三顆不進「平台個人化」名單，要一起改。
             */

            bindings = <
&none  &kp LA(F4)  &kp LC(W)  &kp LC(E)  &kp LC(Y)  &kp LC(T)  &kp LC(U)  &kp LC(BSPC)  &kp LC(DEL)  &kp LC(K)  &to 0  &none  &none  &mt (LALT) LC(A)  &mt (LGUI) LC(S)  &mt (LCTRL) LC(D)  &mt (LSHFT) LC(F)  &kp LC(L)  &lt 7 HOME  &kp LC(LEFT)  &kp LC(RIGHT)  &kp END  &kp LC(LS(T))  &none  &none  &kp LC(Z)  &kp LC(X)  &kp LC(C)  &kp LC(V)  &kp LC(B)  &kp LS(HOME)  &kp LC(LS(LEFT))  &kp LC(LS(RIGHT))  &kp LS(END)  &kp LC(W)  &none  &kp LS(LC(LA(LG(GRAVE))))  &sl 5  &none  &td_hint_rep  &td_hint  &kp F19
            >;
        };

        layer_5 {
            display-name = "FUN";
            bindings = <
&none  &kp F12  &kp F7  &kp F8  &kp F9  &kp C_VOL_UP  &kp LC(LG(N1))  &kp LC(LG(N2))  &kp LC(LG(N3))  &kp LC(LG(N4))  &kp LG(LS(S))  &none  &none  &kp F11  &kp F4  &kp F5  &kp F6  &kp C_MUTE  &kp LS(LC(LA(LG(Y))))  &kp LSHFT  &kp LCTRL  &kp LGUI  &kp LALT  &none  &none  &kp F10  &kp F1  &kp F2  &kp F3  &kp C_VOL_DN  &kp LS(LC(LA(LG(M))))  &kp LS(LC(LA(LG(A))))  &kp LS(LC(LA(LG(N))))  &kp LS(LC(LA(LG(G))))  &kp LS(LC(LA(LG(O))))  &none  &kp C_PREV  &kp C_PP  &kp C_NEXT  &kp LS(LC(LA(LG(P))))  &none  &kp LS(LC(LA(LG(V))))
            >;
        };

        layer_6 {
            /*
             * ── 2026-11-05：X(26) 的左鍵改成 &drag_lclk ──
             * 仍是按住的左鍵，但按住期間升起 DRAG(13)：C(27) = 滾輪下、
             * V(28) = 滾輪上（同 SCRL 的 J / K），拖曳選取時可以邊按邊捲。
             *
             * ── 2026-11-04：右手全部改回 &trans，左拇指內側(38)的 &mo 9 也拔掉 ──
             * 用 PAD 後馬上打字會一直離不開 PAD 層（J/K/L/N/M 等是點擊/&mo，
             * 會續命或吃掉字）。下面 09-24 那段說明的右手滑鼠配置已不再適用；
             * 保留 10 的 &to 0 當逃生鍵。layer_9（CUR+）沒有入口了。
             *
             * ── 2026-09-24：右半整隻手變成一套完整滑鼠 ────────────────────
             *
             * 觸控板在**右拇指底下**，所以「右拇指調速鍵」從來就按不到——手指
             * 在板上的時候那三顆拇指是被佔住的。但**其餘四指是空的**，於是整組
             * 滑鼠功能改掛到右手，變成「拇指推游標、四指按鍵」的單手操作：
             *
             *   位置 19 (J) &trans    → &mkp LCLK   左鍵（食指 home）
             *   位置 20 (K) &trans    → &mkp RCLK   右鍵（中指 home）
             *   位置 21 (L) &trans    → &mkp MCLK   中鍵（無名指 home）
             *   位置 30 (N) &mkp LCLK → &mo 8       CUR-（慢）
             *   位置 31 (M) &mkp RCLK → &mo 9       CUR+（快）
             *   位置 39/40（右拇指內／中）&mo 8 / &mo 9 → &trans
             *   位置 6  (Y) &mkp MCLK → &trans      （舊的零散點擊，收掉）
             *
             * 捲動**不用另外配**，本來就有兩條純右手的路：
             *   雙指滑觸控板（TPS43 硬體手勢，見 toucan_right.overlay 的 scroll）
             *   按住 H ＋ 拖板（18 是 &trans ⇒ 落到 BASE 的 &lt 7 H，進 SCRL）
             * ⇒ **位置 18 (H) 必須維持 &trans**，填東西進去會把一手捲動弄不見。
             *
             * 左手 26/27/28 的 LCLK/RCLK/MCLK 與左拇指 37/38 的調速**都保留**，
             * 兩手各一套、互不干擾。
             *
             * 順帶修掉一個誤觸：N / M 原本是 LCLK / RCLK，觸控板 600 ms timeout
             * 內打到 n / m 會**真的點下去**。換成 &mo 之後，誤觸代價只剩「升起
             * 一個 42 格全 &trans 的層」，等於沒事。
             *
             * ⚠️ 代價講清楚：J / K / L 現在是點擊鍵，**摸完觸控板 600 ms 內打到
             *    j / k / l 會真的點下去**。這正是檔頭在講的那個誤觸問題，這一版
             *    刻意把面積擴大到右手，換一手完整滑鼠。反方向有
             *    require-prior-idle-ms = 200 擋著（剛打完字不升 PAD 層），
             *    但「先摸板、再打字」只靠 timeout。常誤觸的話下一步是把點擊往下
             *    移到 32/33/34（`,` `.` `/`），**不要**去縮 listener 的 timeout
             *    ——那會弄壞「先定位、停手、再點擊」。
             *
             * ⚠️ 這些鍵能按是因為 toucan-trackpad.dtsi 的 excluded-positions 是
             *    空的（＝沒有任何鍵會關掉 PAD 層）。那裡改成非空的話，這五顆會
             *    變成「一按就把 PAD 層踢掉」，整組直接失效。
             *
             * ⚠️ 右半最外欄（位置 11 / 23 / 35）**沒焊開關**，不要往那裡放東西。
             *    左半的 0 / 12 / 24 同理。
             */

            display-name = "PAD";
            bindings = <
&trans  &trans  &trans  &trans  &trans  &trans  &trans  &trans  &trans  &trans  &to 0  &trans  &trans  &kp LALT  &ctrl_click  &kp LCTRL  &kp LSHFT  &trans  &trans  &trans  &trans  &trans  &trans  &trans  &trans  &trans  &drag_lclk  &mkp RCLK  &mkp MCLK  &trans  &trans  &trans  &trans  &trans  &trans  &trans  &mo 8  &trans  &trans  &trans  &trans  &trans
            >;
        };

        layer_7 {
            /*
             * 垂直（位置 2/4 與 19/20 的 `&msc MOVE_Y`）方向與觸控板一致，
             * 採 macOS 的 natural（內容跟著手指走）語意。
             * 觸控板方向在 toucan-trackpad.dtsi 的 INPUT_TRANSFORM_Y_INVERT。
             *
             * ── 2026-09-22：水平（H / L）對調 ─────────────────────────────
             *   位置 18 (H) = &msc MOVE_X(-25)   ← 原本 (25)
             *   位置 21 (L) = &msc MOVE_X(25)    ← 原本 (-25)
             * 兩個平台分支都有這一版（macOS 那邊的註解寫的是「兩個分支同步」）。
             * 這裡原本寫「macOS 分支尚未同步」是過期資訊，2026-09-24 更正。
             *
             * ⚠️ 真正漏改的是 SCR-(10) / SCR+(11) —— 那兩層一路停在舊方向，
             *    按著拇指調速時水平就反過來。2026-09-24 已一併對調，三檔同向。
             *
             * ── 2026-09-24：左手照 Piantor L8 重排 ───────────────────────
             *
             *   位置 1  (Q)  &kp LC(PLUS)      → &kp ESC
             *   位置 5  (T)  &kp LC(R)         → &kp PAGE_UP
             *   位置 13 (A)  &msc MOVE_X(25)   → &kp LC(PLUS)     放大
             *   位置 17 (G)  &msc MOVE_X(-25)  → &kp PAGE_DOWN
             *   位置 29 (B)  &kp ESC           → &td_end_home     單 End / 雙 Home
             *
             * 位置 25 (Z) 的縮小與拇指 36 的 &kp LC(N0)（歸零）沒動，跟新的 A
             * 湊成完整一組縮放。&td_end_home 的理由見上方 behaviors。
             *
             * ⚠️ 左手從此沒有水平滾輪 —— A / G 讓出去了，水平只剩右手 H / L。
             *    SCR-(10) / SCR+(11) 的 13 / 17 也一起改成 &trans，不然按著
             *    調速拇指的時候那兩顆又會變回水平滾動。
             *
             * ⚠️ &kp LC(R)（重新整理）直接拿掉，沒有另外找位置。Piantor 把它
             *    放在右拇指最外側，但 Toucan 那三顆是 SCR± 調速與 F19，不讓位。
             *
             * 還沒對齊 Piantor 的只剩滑鼠鍵：Piantor 是 X=BTN1 / C=BTN4（上一頁）
             * / V=BTN2，Toucan 是 26=LCLK / 27=RCLK / 28=MCLK。Toucan 這邊刻意
             * 保留右鍵與中鍵，沒有跟著改。
             */

            display-name = "SCRL";
            bindings = <
&trans  &kp LC(W)  &kp HOME  &kp PAGE_DOWN  &kp PAGE_UP  &kp LC(R)  &kp LC(PG_UP)  &kp LC(PG_DN)  &kp LA(LEFT)  &kp LA(RIGHT)  &to 0  &trans  &trans  &kp LC(PLUS)  &kp END  &kp LA(LEFT)  &kp LA(RIGHT)  &trans  &msc (MOVE_X(-25))  &msc MOVE_Y(25)  &msc (MOVE_Y(-25))  &msc MOVE_X(25)  &kp LC(LS(T))  &trans  &trans  &kp LC(MINUS)  &mkp LCLK  &mkp RCLK  &mkp MCLK  &td_end_home  &kp END  &kp PAGE_DOWN  &kp PAGE_UP  &kp HOME  &kp LC(W)  &trans  &ctrl_click  &mo 10  &mo 11  &mo 10  &mo 11  &kp F19
            >;
        };

        layer_8 {
            display-name = "CUR-";
            bindings = <
&trans  &trans  &trans  &trans  &trans  &trans  &trans  &trans  &trans  &trans  &trans  &trans  &trans  &trans  &trans  &trans  &trans  &trans  &trans  &trans  &trans  &trans  &trans  &trans  &trans  &trans  &trans  &trans  &trans  &trans  &trans  &trans  &trans  &trans  &trans  &trans  &trans  &trans  &trans  &trans  &trans  &trans
            >;
        };

        layer_9 {
            display-name = "CUR+";
            bindings = <
&trans  &trans  &trans  &trans  &trans  &trans  &trans  &trans  &trans  &trans  &trans  &trans  &trans  &trans  &trans  &trans  &trans  &trans  &trans  &trans  &trans  &trans  &trans  &trans  &trans  &trans  &trans  &trans  &trans  &trans  &trans  &trans  &trans  &trans  &trans  &trans  &trans  &trans  &trans  &trans  &trans  &trans
            >;
        };

        layer_10 {
            /* 滾輪按鍵方向同 layer_7（natural），兩個平台分支相同。 */

            display-name = "SCR-";
            bindings = <
&trans  &trans  &trans  &trans  &trans  &trans  &trans  &trans  &trans  &trans  &trans  &trans  &trans  &trans  &trans  &trans  &trans  &trans  &msc (MOVE_X(-10))  &msc MOVE_Y(10)  &msc (MOVE_Y(-10))  &msc MOVE_X(10)  &trans  &trans  &trans  &trans  &trans  &trans  &trans  &trans  &trans  &trans  &trans  &trans  &trans  &trans  &trans  &trans  &trans  &trans  &trans  &trans
            >;
        };

        layer_11 {
            /* 滾輪按鍵方向同 layer_7（natural），兩個平台分支相同。 */

            display-name = "SCR+";
            bindings = <
&trans  &trans  &trans  &trans  &trans  &trans  &trans  &trans  &trans  &trans  &trans  &trans  &trans  &trans  &trans  &trans  &trans  &trans  &msc (MOVE_X(-40))  &msc MOVE_Y(40)  &msc (MOVE_Y(-40))  &msc MOVE_X(40)  &trans  &trans  &trans  &trans  &trans  &trans  &trans  &trans  &trans  &trans  &trans  &trans  &trans  &trans  &trans  &trans  &trans  &trans  &trans  &trans
            >;
        };

        layer_12 {
            display-name = "BT";
            bindings = <
&none  &bt BT_SEL 0  &bt BT_SEL 1  &bt BT_SEL 2  &bt BT_SEL 3  &bt BT_SEL 4  &trans  &trans  &trans  &trans  &to 0  &none  &none  &out OUT_USB  &out OUT_BLE  &out OUT_TOG  &trans  &trans  &trans  &trans  &trans  &trans  &trans  &none  &none  &bt BT_CLR  &trans  &trans  &trans  &bootloader  &bootloader  &trans  &trans  &trans  &trans  &none  &trans  &trans  &trans  &trans  &trans  &trans
            >;
        };

        layer_13 {
            /*
             * 只由 PAD 的 X(26) &drag_lclk 按住時升起。C(27) / V(28) 照抄
             * SCRL 的 J(19) / K(20)，方向一樣是 natural。
             * 觸控板處理鏈（toucan-trackpad.dtsi）刻意不含 13 ⇒ 游標照常移動，
             * 拖曳不受影響。
             */

            display-name = "DRAG";
            bindings = <
&trans  &trans  &trans  &trans  &trans  &trans  &trans  &trans  &trans  &trans  &trans  &trans  &trans  &trans  &trans  &trans  &trans  &trans  &trans  &trans  &trans  &trans  &trans  &trans  &trans  &trans  &trans  &msc MOVE_Y(25)  &msc (MOVE_Y(-25))  &trans  &trans  &trans  &trans  &trans  &trans  &trans  &trans  &trans  &trans  &trans  &trans  &trans
            >;
        };
    };
};
